# MCAN_ECC_AGGR_24018000h register map
Vendor: Texas Instruments
Peripheral module from a debugger description file (folder AM275x).
Registers are 32-bit, access not given, reset 0x0 unless marked. A register's access mark holds for its fields unless they carry their own. Offsets are as the file gives them; lines under a group give offsets from that group; [hi:lo] are bit positions; {n}, {i} and the like mark numbered series; 'fields as' and 'values as' point back to an identical list; <NAME> marks a mode.

## ecc_aggr
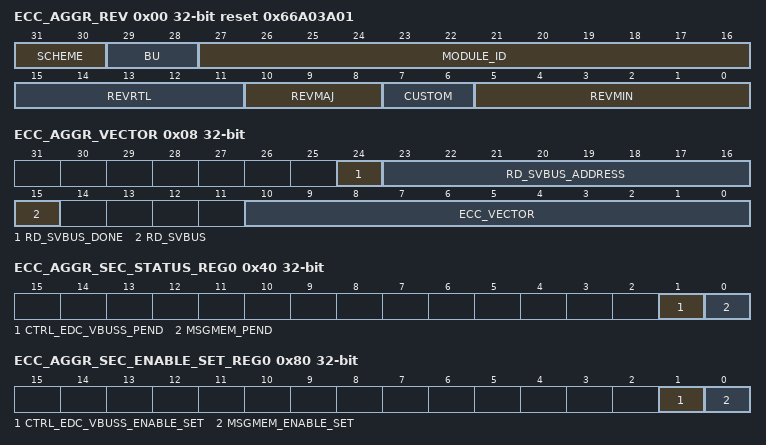
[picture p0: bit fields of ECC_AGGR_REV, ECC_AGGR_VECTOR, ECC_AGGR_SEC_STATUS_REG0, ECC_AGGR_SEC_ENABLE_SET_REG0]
0x00 ECC_AGGR_REV ro reset 0x66A03A01 — Revision parameters
  [31:30] SCHEME
  [29:28] BU — Business Unit
  [27:16] MODULE_ID
  [15:11] REVRTL — RTL Version
  [10:8] REVMAJ — Major Version
  [7:6] CUSTOM — Custom Version
  [5:0] REVMIN — Minor Version
0x08 ECC_AGGR_VECTOR — ECC Vector Register
  [24] RD_SVBUS_DONE — Read Done Status to indicate if read on the serial ECC interface is complete, write of any value will clear this bit. (access R/W1TC)
  [23:16] RD_SVBUS_ADDRESS rw — Read Address
  [15] RD_SVBUS — Read Trigger Write 1h to trigger a read on the serial ECC interface. (access R/W1TS)
  [10:0] ECC_VECTOR rw — ECC RAM ID Value written to select the corresponding ECC RAM for control or status.
0x0C ECC_AGGR_STAT ro reset 0x2 — Misc Status
  [10:0] NUM_RAMS — Number of RAMs Indicates the number of RAMs serviced by the ECC Aggregator.
0x3C ECC_AGGR_SEC_EOI_REG — EOI Register
  [0] EOI_WR — Single Error Correction End Of Interrupt (SEC EOI) (access R/W1TS)
0x40 ECC_AGGR_SEC_STATUS_REG0 — Interrupt Status Register 0
  [1] CTRL_EDC_VBUSS_PEND — Interrupt Pending Status for CTRL_EDC_VBUSS_PEND (access R/W1TS)
  [0] MSGMEM_PEND — Interrupt Pending Status for MSGMEM_PEND (access R/W1TS)
0x80 ECC_AGGR_SEC_ENABLE_SET_REG0 — Interrupt Enable Set Register 0
  [1] CTRL_EDC_VBUSS_ENABLE_SET — Interrupt Enable Set for CTRL_EDC_VBUSS_PEND (access R/W1TS)
  [0] MSGMEM_ENABLE_SET — Interrupt Enable Set for MSGMEM_PEND (access R/W1TS)
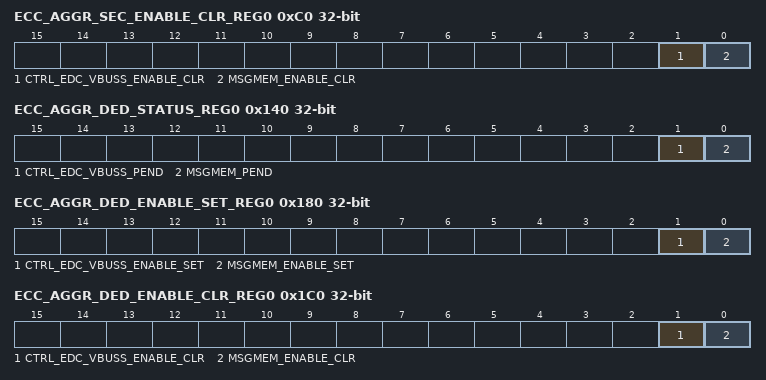
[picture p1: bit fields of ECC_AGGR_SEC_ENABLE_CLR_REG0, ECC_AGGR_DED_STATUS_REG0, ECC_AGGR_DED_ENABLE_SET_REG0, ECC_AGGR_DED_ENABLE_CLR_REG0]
0xC0 ECC_AGGR_SEC_ENABLE_CLR_REG0 — Interrupt Enable Clear Register 0
  [1] CTRL_EDC_VBUSS_ENABLE_CLR — Interrupt Enable Clear for CTRL_EDC_VBUSS_PEND (access R/W1TC)
  [0] MSGMEM_ENABLE_CLR — Interrupt Enable Clear for MSGMEM_PEND (access R/W1TC)
0x13C ECC_AGGR_DED_EOI_REG — EOI Register
  [0] EOI_WR — Double Error Correction End Of Interrupt (DED EOI) (access R/W1TS)
0x140 ECC_AGGR_DED_STATUS_REG0 — Interrupt Status Register 0
  fields as ECC_AGGR_SEC_STATUS_REG0
0x180 ECC_AGGR_DED_ENABLE_SET_REG0 — Interrupt Enable Set Register 0
  fields as ECC_AGGR_SEC_ENABLE_SET_REG0
0x1C0 ECC_AGGR_DED_ENABLE_CLR_REG0 — Interrupt Enable Clear Register 0
  fields as ECC_AGGR_SEC_ENABLE_CLR_REG0
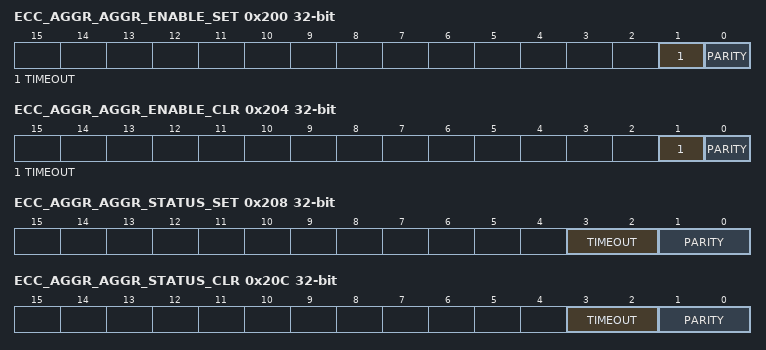
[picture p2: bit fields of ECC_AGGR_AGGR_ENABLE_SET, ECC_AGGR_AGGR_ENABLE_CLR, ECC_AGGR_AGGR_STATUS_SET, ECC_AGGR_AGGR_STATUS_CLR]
0x200 ECC_AGGR_AGGR_ENABLE_SET — AGGR interrupt enable set Register
  [1] TIMEOUT — Interrupt Enable Set for Serial ECC Interface Timeout Errors (access R/W1TS)
  [0] PARITY — Interrupt Enable Set for Parity Errors (access R/W1TS)
0x204 ECC_AGGR_AGGR_ENABLE_CLR — AGGR interrupt enable clear Register
  [1] TIMEOUT — Interrupt Enable Clear for Serial ECC Interface Timeout Errors (access R/W1TC)
  [0] PARITY — Interrupt Enable Clear for Parity Errors (access R/W1TC)
0x208 ECC_AGGR_AGGR_STATUS_SET — AGGR interrupt status set Register
  [3:2] TIMEOUT — Interrupt Status Set for Serial ECC Interface Timeout Errors (access R/WI)
  [1:0] PARITY — Interrupt Status Set for Parity Errors (access R/WI)
0x20C ECC_AGGR_AGGR_STATUS_CLR — AGGR interrupt status clear Register
  [3:2] TIMEOUT — Interrupt Status Clear for Serial ECC Interface Timeout Errors (access R/WD)
  [1:0] PARITY — Interrupt Status Clear for Parity Errors (access R/WD)
